# TC37XPD register map
Vendor: Infineon; Series: ATVMC; File version: 100
CPU: other r0p0, little endian, MPU, FPU, vendor SysTick, 4 interrupt priority bits
Registers are 32-bit, read-write, reset 0x0 unless marked. A register's access mark holds for its fields unless they carry their own. Offsets are from the block's base; [hi:lo] are bit positions; lines under a group give offsets from that group; {n}, {i} and the like mark numbered series; 'fields as' and 'values as' point back to an identical list.

## INT
Base 0xF0037000
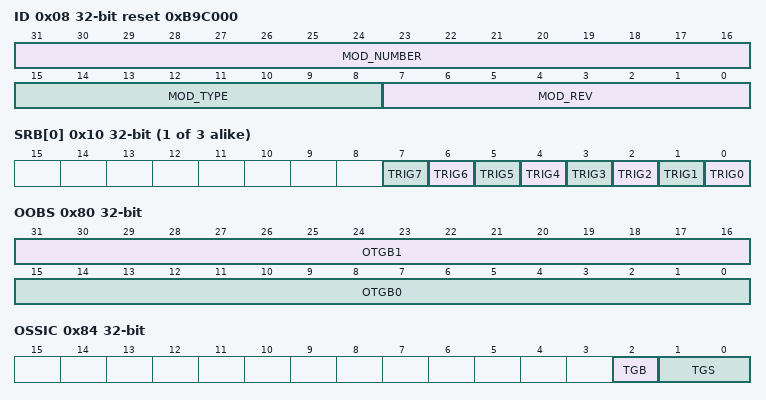
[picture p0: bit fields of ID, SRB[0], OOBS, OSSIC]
0x08 ID ro reset 0xB9C000 (reset mask 0xFFFFFF00) — Module Identification Register resetvalue={Application Reset:0x0B9C000}
  [31:16] MOD_NUMBER — Module Number Value. This bit field defines a module identification number. The value for the Interrupt Router module is 009Bh.
  [15:8] MOD_TYPE — Module Type. The bit field is set to C0 which defines the module as a 32 bit module.
  [7:0] MOD_REV — Module Revision Number. This bit field defines the module revision number. The value of a module revision starts with 01 first revision .
{0x10+4i} SRB[{i}] (i=0..2) wo — Service Request Broadcast Register 0 resetvalue={Application Reset:0x0}
  [n] TRIG{n} (n=0..7) — General Purpose Service Request Trigger 7. This bit is always read as 0.
0x80 OOBS ro — OTGM OTGB0 1 Status resetvalue={Application Reset:0x0}
  [31:16] OTGB1 — Status of OTGB1
  [15:0] OTGB0 — Status of OTGB0
0x84 OSSIC — OTGM SSI Control resetvalue={Application Reset:0x0}
  [2] TGB — OTGB0 1 Bus Select
  [1:0] TGS — Trigger Set for OTGB0 1
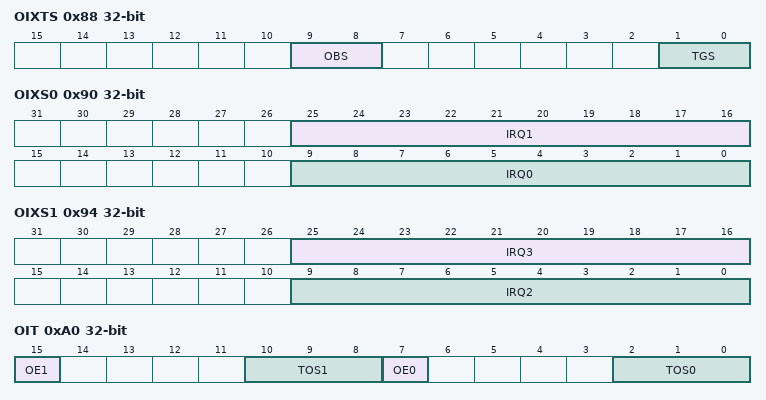
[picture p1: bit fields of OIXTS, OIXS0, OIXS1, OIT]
0x88 OIXTS — OTGM IRQ MUX Trigger Set Select resetvalue={Application Reset:0x0}
  [9:8] OBS — Overlay Byte Select
  [1:0] TGS — Trigger Set Select for OTGB0 1 Overlay
0x8C OIXMS — OTGM IRQ MUX Missed IRQ Select resetvalue={Application Reset:0x0}
  [9:0] MIRQ — SRN Index for Missed Interrupt Trigger
0x90 OIXS0 — OTGM IRQ MUX Select 0 resetvalue={Application Reset:0x0}
  [25:16] IRQ1 — SRN Index for Interrupt Trigger 1
  [9:0] IRQ0 — SRN Index for Interrupt Trigger 0
0x94 OIXS1 — OTGM IRQ MUX Select 1 resetvalue={Application Reset:0x0}
  [25:16] IRQ3 — SRN Index for Interrupt Trigger 3
  [9:0] IRQ2 — SRN Index for Interrupt Trigger 2
0xA0 OIT — OTGM IRQ Trace resetvalue={Application Reset:0x0}
  [15] OE1 — Output Enable for OTGB1
  [10:8] TOS1 — Type of Service for Observation on OTGB1. Trigger Set TS16 SP Family concept encoding compatible with SRC.TOS In products where the CPUx is not implemented the related TOS encoding will not be used and treated as RESERVED.
  [7] OE0 — Output Enable for OTGB0
  [2:0] TOS0 — Type of Service for Observation on OTGB0. Trigger Set TS16 SP Family concept encoding compatible with SRC.TOS In products where the CPUx is not implemented the related TOS encoding will not be used and treated as RESERVED.
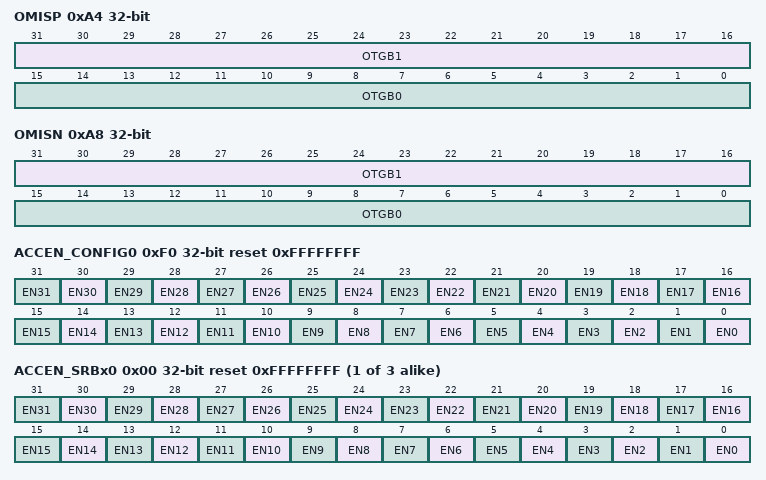
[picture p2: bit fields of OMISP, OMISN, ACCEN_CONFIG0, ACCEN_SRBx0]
0xA4 OMISP — OTGM MCDS I F Sensitivity Posedge resetvalue={Application Reset:0x0}
  [31:16] OTGB1 — Bitwise Posedge Sensitivity for OTGB1. If a bit is set an OTGB value will be written to MCDS on a rising edge of the associated OTGB1 bit.
  [15:0] OTGB0 — Bitwise Posedge Sensitivity for OTGB0. If a bit is set an OTGB value will be written to MCDS on a rising edge of the associated OTGB0 bit.
0xA8 OMISN — OTGM MCDS I F Sensitivity Negedge resetvalue={Application Reset:0x0}
  [31:16] OTGB1 — Bitwise Negedge Sensitivity for OTGB1. If a bit is set an OTGB value will be written to MCDS on a falling edge of the associated OTGB1 bit.
  [15:0] OTGB0 — Bitwise Negedge Sensitivity for OTGB0. If a bit is set an OTGB value will be written to MCDS on a falling edge of the associated OTGB0 bit.
0xF0 ACCEN_CONFIG0 reset 0xFFFFFFFF — Access Enable covering all INT ECRx and all SRCy 15 0 Register 0 resetvalue={Application Reset:0x0FFFFFFFF}
  [n] EN{n} (n=0..31) — Access Enable for Master TAG ID 31 EN31. This bit enables write access to the module kernel addresses for transactions with the Master TAG ID x
{0x100+8i} ACCEN[{i}] (i=0..2) group
  0x00 ACCEN_SRBx0 reset 0xFFFFFFFF — Access Enable covering SRB0 Register 0 resetvalue={Application Reset:0x0FFFFFFFF}
    [n] EN{n} (n=0..31) — Access Enable for Master TAG ID 31. This bit enables write access to the module kernel addresses for transactions with the Master TAG ID i
{0x180+8i} ACCEN_SRC[{i}] (i=0..3) group
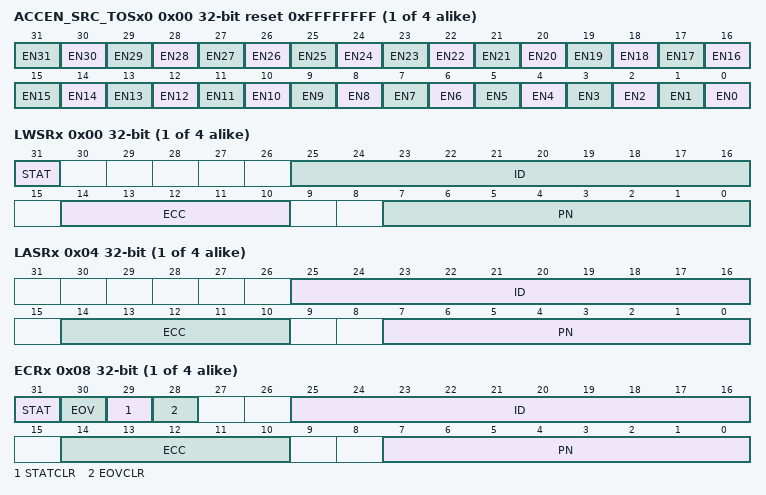
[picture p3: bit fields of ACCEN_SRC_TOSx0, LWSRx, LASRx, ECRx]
  0x00 ACCEN_SRC_TOSx0 reset 0xFFFFFFFF — Access Enable covering all SRCx 31 16 mapped to ICU0 Register 0 resetvalue={Application Reset:0x0FFFFFFFF}
    fields as ACCEN[0].ACCEN_SRBx0
{0x200+0x10*i} CH[{i}] (i=0..3) group
  0x00 LWSRx ro — Latest Winning Service Request Register 0 related to ICU0 resetvalue={Application Reset:0x0}
    [31] STAT — LWSR Register Status. The STAT register indicates if the PN ECC and ID bit fields are still valid. They are still valid if the interrupt from the SRN identified by ID is still pending. If the ICU does not have an winner because no interrupt is pending or not yet arbitrated then it clears the STAT bit.
    [25:16] ID — Latest Winner Index Number. This bit field shows the ID number of the last winning SRN. This bit field is only valid if STAT is set to 1
    [14:10] ECC — Latest Winner ECC. This bit field shows the ECC field SRN.ECC that was transferred from the last winning SRN to the ICU. This bit field is only valid if STAT is set to 1. In the current implementation the ECC code is only used for error detection. Detected errors are reported to the SMU but not corrected.
    [7:0] PN — Latest Winner Priority Number. This bit field shows the Priority Number of a pending service request that won the last arbitration round. This bit field is only valid if STAT is set to 1
  0x04 LASRx ro — Last Acknowledged Service Request Register 0 related to ICU0 resetvalue={Application Reset:0x0}
    [25:16] ID — Last Acknowledged Interrupt SRN ID. This bit field shows the ID number of the last acknowledged service request as sent by the service provider with acknowledge
    [14:10] ECC — Last Acknowledged Interrupt ECC. This bit field shows the ECC value of the last acknowledged service request as send by the service provider with acknowledge In the current implementation the ECC code is only used for error detection. Detected errors are reported to the SMU but not corrected.
    [7:0] PN — Last Acknowledged Service Request Priority Number. This bit field shows the Priority Number of the last acknowledged service request
  0x08 ECRx access per field — Error Capture Register 0 related to ICU0 resetvalue={Application Reset:0x0}
    [31] STAT ro — Error Status Bit. The Error Status Bit is set whenever an ECC was detected by the ICU.
    [30] EOV ro — Error Overflow Bit. The bit is set if an ECC error was detected by the ICU while ECR.STAT 180 1 180 Error Overflow situation .
    [29] STATCLR wo — Error Status Bit. The STATCLR bit is used to clear the STAT bit.
    [28] EOVCLR wo — Error Overflow Bit. The EOVCLR bit is used to clear the EOV bit. The EOV bit must be cleared togehter with the STAT bit.
    [25:16] ID rw — Service Request Node ID. This bit field shows the ID of the last service request where an error was detected. Bit field can be modified by writing to it
    [14:10] ECC rw — Service Request ECC. This bit field shows the ECC of the last service request where an error was detected. Bit field can be modified by writing to it. This bit field can be modified by Writing to SRC 23 16 byte write Writing to SRC 31 16 16 bit write
    [7:0] PN rw — Service Request Priority Number. This bit field shows the priority number of the last service request where an error was detected. Bit field can be modified by writing to it.
